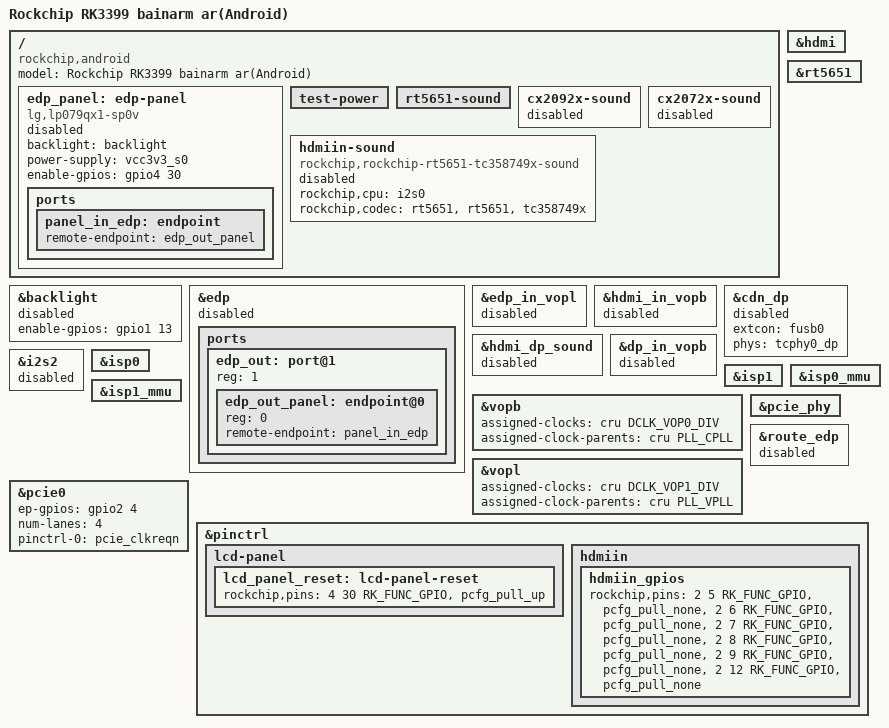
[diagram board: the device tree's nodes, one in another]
/*
 * Copyright (c) 2016 Fuzhou Rockchip Electronics Co., Ltd
 *
 * This file is dual-licensed: you can use it either under the terms
 * of the GPL or the X11 license, at your option. Note that this dual
 * licensing only applies to this file, and not this project as a
 * whole.
 *
 *  a) This file is free software; you can redistribute it and/or
 *     modify it under the terms of the GNU General Public License as
 *     published by the Free Software Foundation; either version 2 of the
 *     License, or (at your option) any later version.
 *
 *     This file is distributed in the hope that it will be useful,
 *     but WITHOUT ANY WARRANTY; without even the implied warranty of
 *     MERCHANTABILITY or FITNESS FOR A PARTICULAR PURPOSE.  See the
 *     GNU General Public License for more details.
 *
 * Or, alternatively,
 *
 *  b) Permission is hereby granted, free of charge, to any person
 *     obtaining a copy of this software and associated documentation
 *     files (the "Software"), to deal in the Software without
 *     restriction, including without limitation the rights to use,
 *     copy, modify, merge, publish, distribute, sublicense, and/or
 *     sell copies of the Software, and to permit persons to whom the
 *     Software is furnished to do so, subject to the following
 *     conditions:
 *
 *     The above copyright notice and this permission notice shall be
 *     included in all copies or substantial portions of the Software.
 *
 *     THE SOFTWARE IS PROVIDED "AS IS", WITHOUT WARRANTY OF ANY KIND,
 *     EXPRESS OR IMPLIED, INCLUDING BUT NOT LIMITED TO THE WARRANTIES
 *     OF MERCHANTABILITY, FITNESS FOR A PARTICULAR PURPOSE AND
 *     NONINFRINGEMENT. IN NO EVENT SHALL THE AUTHORS OR COPYRIGHT
 *     HOLDERS BE LIABLE FOR ANY CLAIM, DAMAGES OR OTHER LIABILITY,
 *     WHETHER IN AN ACTION OF CONTRACT, TORT OR OTHERWISE, ARISING
 *     FROM, OUT OF OR IN CONNECTION WITH THE SOFTWARE OR THE USE OR
 *     OTHER DEALINGS IN THE SOFTWARE.
 */

/dts-v1/;

#include "rk3399-bainarm-ar.dtsi"
#include "rk3399-android.dtsi"
#include "rk3399-vop-clk-set.dtsi"

/ {
	model = "Rockchip RK3399 bainarm ar(Android)";
	compatible = "rockchip,android", "rockchip,rk3399-bainarm-android-ar", "rockchip,rk3399";

	edp_panel: edp-panel {
		status = "disabled";
		compatible = "lg,lp079qx1-sp0v", "panel-simple";
		backlight = <&backlight>;
		power-supply = <&vcc3v3_s0>;
		enable-gpios = <&gpio4 30 GPIO_ACTIVE_HIGH>;

		ports {
			panel_in_edp: endpoint {
				remote-endpoint = <&edp_out_panel>;
			};
		};
	};

	test-power {
		status = "okay";
	};

	rt5651-sound {
		status = "okay";
	};

	cx2092x-sound {
		status = "disabled";
	};

	cx2072x-sound {
		status = "disabled";
	};

	hdmiin-sound {
		compatible = "rockchip,rockchip-rt5651-tc358749x-sound";
		rockchip,cpu = <&i2s0>;
		rockchip,codec = <&rt5651 &rt5651 &tc358749x>;
		status = "disabled";
	};
};

&backlight {
	status = "disabled";
	enable-gpios = <&gpio1 13 GPIO_ACTIVE_HIGH>;
};

&edp {
	status = "disabled";

	ports {
		edp_out: port@1 {
			reg = <1>;
			#address-cells = <1>;
			#size-cells = <0>;

			edp_out_panel: endpoint@0 {
				reg = <0>;
				remote-endpoint = <&panel_in_edp>;
			};
		};
	};
};

&edp_in_vopl {
	status = "disabled";
};

&hdmi {
	status = "okay";
};

&hdmi_in_vopb {
	status = "disabled";
};

&rt5651 {
	status = "okay";
};

&cdn_dp {
	status = "disabled";
	extcon = <&fusb0>;
	phys = <&tcphy0_dp>;
};

&hdmi_dp_sound {
	status = "disabled";
};

&dp_in_vopb {
	status = "disabled";
};

&i2s2 {
	status = "disabled";
};

&isp0 {
	status = "okay";
};

&isp1 {
	status = "okay";
};

&isp0_mmu {
	status = "okay";
};

&isp1_mmu {
	status = "okay";
};

&vopb {
	assigned-clocks = <&cru DCLK_VOP0_DIV>;
	assigned-clock-parents = <&cru PLL_CPLL>;
};

&vopl {
	assigned-clocks = <&cru DCLK_VOP1_DIV>;
	assigned-clock-parents = <&cru PLL_VPLL>;
};

&pcie_phy {
	status = "okay";
};

&pcie0 {
	ep-gpios = <&gpio2 4 GPIO_ACTIVE_HIGH>;
	num-lanes = <4>;
	pinctrl-names = "default";
	pinctrl-0 = <&pcie_clkreqn>;
	status = "okay";
};

&route_edp {
	status = "disabled";
};

&pinctrl {
	lcd-panel {
		lcd_panel_reset: lcd-panel-reset {
			rockchip,pins = <4 30 RK_FUNC_GPIO &pcfg_pull_up>;
		};
	};

	hdmiin {
		hdmiin_gpios: hdmiin_gpios {
		rockchip,pins =
				<2 5 RK_FUNC_GPIO &pcfg_pull_none>,
				<2 6 RK_FUNC_GPIO &pcfg_pull_none>,
				<2 7 RK_FUNC_GPIO &pcfg_pull_none>,
				<2 8 RK_FUNC_GPIO &pcfg_pull_none>,
				<2 9 RK_FUNC_GPIO &pcfg_pull_none>,
				<2 12 RK_FUNC_GPIO &pcfg_pull_none>;
		};
	};
};

